VERSION "1.0.0"

NS_ :

BS_:

BU_: SENSOR_ECU TESTER PEER_ECU

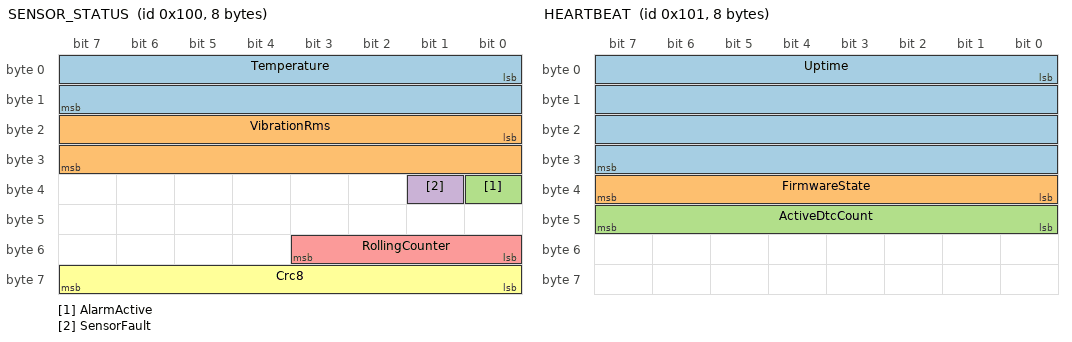
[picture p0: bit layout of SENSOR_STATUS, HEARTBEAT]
BO_ 256 SENSOR_STATUS: 8 SENSOR_ECU
 SG_ Temperature : 0|16@1- (0.1,0) [-3276.8|3276.7] "degC" TESTER,PEER_ECU
 SG_ VibrationRms : 16|16@1+ (0.01,0) [0|655.35] "mm/s" TESTER,PEER_ECU
 SG_ AlarmActive : 32|1@1+ (1,0) [0|1] "" TESTER,PEER_ECU
 SG_ SensorFault : 33|1@1+ (1,0) [0|1] "" TESTER,PEER_ECU
 SG_ RollingCounter : 48|4@1+ (1,0) [0|15] "" TESTER,PEER_ECU
 SG_ Crc8 : 56|8@1+ (1,0) [0|255] "" TESTER,PEER_ECU

BO_ 257 HEARTBEAT: 8 SENSOR_ECU
 SG_ Uptime : 0|32@1+ (1,0) [0|4294967295] "s" TESTER,PEER_ECU
 SG_ FirmwareState : 32|8@1+ (1,0) [0|255] "" TESTER,PEER_ECU
 SG_ ActiveDtcCount : 40|8@1+ (1,0) [0|255] "" TESTER,PEER_ECU

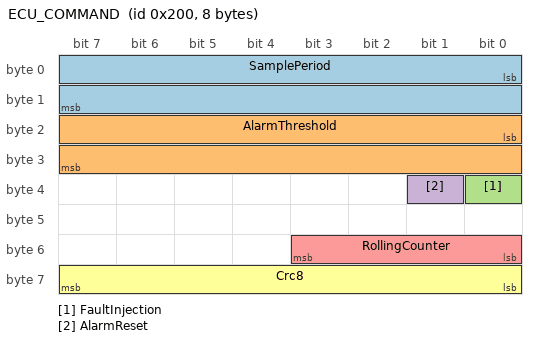
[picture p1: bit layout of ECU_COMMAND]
BO_ 512 ECU_COMMAND: 8 PEER_ECU
 SG_ SamplePeriod : 0|16@1+ (1,0) [0|10000] "ms" SENSOR_ECU
 SG_ AlarmThreshold : 16|16@1- (0.1,0) [-3276.8|3276.7] "degC" SENSOR_ECU
 SG_ FaultInjection : 32|1@1+ (1,0) [0|1] "" SENSOR_ECU
 SG_ AlarmReset : 33|1@1+ (1,0) [0|1] "" SENSOR_ECU
 SG_ RollingCounter : 48|4@1+ (1,0) [0|15] "" SENSOR_ECU
 SG_ Crc8 : 56|8@1+ (1,0) [0|255] "" SENSOR_ECU

BO_ 2016 UDS_REQUEST: 8 TESTER
 SG_ IsoTpPayload : 0|64@1+ (1,0) [0|0] "" SENSOR_ECU

BO_ 2024 UDS_RESPONSE: 8 SENSOR_ECU
 SG_ IsoTpPayload : 0|64@1+ (1,0) [0|0] "" TESTER

CM_ BU_ SENSOR_ECU "Zephyr sensor ECU (native_sim or STM32F4 in Renode)";
CM_ BU_ TESTER "Python UDS tester, CAN monitor and integration tests";
CM_ BU_ PEER_ECU "Second node that commands the sensor ECU";
CM_ BO_ 256 "Sensor telemetry, 100 ms cycle, E2E protected (counter + CRC-8 SAE J1850 over bytes 0..6)";
CM_ BO_ 257 "Liveness, 1000 ms cycle";
CM_ BO_ 512 "Configuration command, on event, E2E protected; a repeated counter is rejected";
CM_ BO_ 2016 "UDS physical request, ISO-TP framed";
CM_ BO_ 2024 "UDS response, ISO-TP framed";
CM_ SG_ 256 VibrationRms "RMS of a 64 sample window";
CM_ SG_ 256 AlarmActive "Latched: set when Temperature > threshold, cleared by an alarm reset";
CM_ SG_ 256 SensorFault "Temperature outside -40.0..125.0 degC";
CM_ SG_ 512 SamplePeriod "10..10000 ms, 0 = leave unchanged";
CM_ SG_ 512 AlarmThreshold "-40.0..125.0 degC, 3276.7 (0x7FFF) = leave unchanged";

BA_DEF_ BO_ "GenMsgCycleTime" INT 0 65535;
BA_DEF_ BO_ "GenMsgSendType" STRING ;
BA_DEF_DEF_ "GenMsgCycleTime" 0;
BA_DEF_DEF_ "GenMsgSendType" "";
BA_ "GenMsgCycleTime" BO_ 256 100;
BA_ "GenMsgCycleTime" BO_ 257 1000;
BA_ "GenMsgSendType" BO_ 256 "Cyclic";
BA_ "GenMsgSendType" BO_ 257 "Cyclic";
BA_ "GenMsgSendType" BO_ 512 "Event";

VAL_ 257 FirmwareState 0 "INIT" 1 "RUN" 2 "DEGRADED" ;
